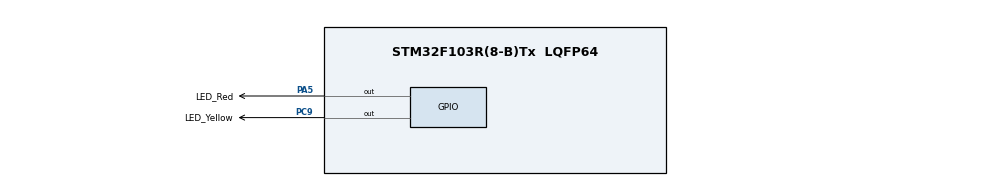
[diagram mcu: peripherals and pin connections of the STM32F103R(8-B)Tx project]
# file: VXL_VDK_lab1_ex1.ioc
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Mcu.Family=STM32F1
Mcu.Name=STM32F103R(8-B)Tx
Mcu.Package=LQFP64
NVIC.PriorityGroup=NVIC_PRIORITYGROUP_4
PA13.Mode=Serial_Wire
PA13.Signal=SYS_JTMS-SWDIO
PA14.Mode=Serial_Wire
PA14.Signal=SYS_JTCK-SWCLK
PA5.GPIO_Label=LED_Red
PA5.Signal=GPIO_Output
PC9.GPIO_Label=LED_Yellow
PC9.Signal=GPIO_Output
ProjectManager.HeapSize=0x200
ProjectManager.StackSize=0x400
ProjectManager.TargetToolchain=STM32CubeIDE
RCC.APB1Freq_Value=8000000
RCC.APB2Freq_Value=8000000
board=custom

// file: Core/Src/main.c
/* USER CODE BEGIN Header */
/**
  ******************************************************************************
  * @file           : main.c
  * @brief          : Main program body
  ******************************************************************************
  * @attention
  *
  * Copyright (c) 2025 STMicroelectronics.
  * All rights reserved.
  *
  * This software is licensed under terms that can be found in the LICENSE file
  * in the root directory of this software component.
  * If no LICENSE file comes with this software, it is provided AS-IS.
  *
  ******************************************************************************
  */
/* USER CODE END Header */
#include "main.h"

/* USER CODE BEGIN PM */
#define TIMER_SCALE 100
/* USER CODE END PM */

/* USER CODE BEGIN PV */
uint16_t timer_cnt = TIMER_SCALE;
uint8_t timer_flag = RESET;
/* USER CODE END PV */

void SystemClock_Config(void);
static void MX_GPIO_Init(void);
/* USER CODE BEGIN PFP */
void timer_handle();
/* USER CODE END PFP */

/* USER CODE BEGIN 0 */
void timer_handle(){
	if(timer_cnt <= 0){
		timer_flag = SET;
		timer_cnt = TIMER_SCALE;
	}
	else --timer_cnt;
}
/* USER CODE END 0 */

int main(void)
{

  /* USER CODE BEGIN 1 */
	  uint8_t led_time = 0;
	  uint8_t led_status = 0;
  /* USER CODE END 1 */

  /* MCU Configuration--------------------------------------------------------*/

  /* Reset of all peripherals, Initializes the Flash interface and the Systick. */
  HAL_Init();

  /* Configure the system clock */
  SystemClock_Config();

  /* Initialize all configured peripherals */
  MX_GPIO_Init();

  /* Infinite loop */
  /* USER CODE BEGIN WHILE */
  while (1)
  {
	  timer_handle();
	  if(timer_flag){
		  timer_flag = RESET;
		  ++led_time;
	  }
	  /*LED BEHAVIOR CODE BEGIN*/
	  if(led_time >=2){
		  led_status = 1 - led_status;
		  led_time = 0;
	  }
	  if(led_status == 0){
		  HAL_GPIO_WritePin(LED_Red_GPIO_Port, LED_Red_Pin, SET);
		  HAL_GPIO_WritePin(LED_Yellow_GPIO_Port, LED_Yellow_Pin, RESET);
	  }else{
		  HAL_GPIO_WritePin(LED_Red_GPIO_Port, LED_Red_Pin, RESET);
		  HAL_GPIO_WritePin(LED_Yellow_GPIO_Port, LED_Yellow_Pin, SET);
	  	  }
	  /*LED BEHAVIOR CODE END*/

	  HAL_Delay(10);
    /* USER CODE END WHILE */

  }
}

void SystemClock_Config(void)
{
  RCC_OscInitTypeDef RCC_OscInitStruct = {0};
  RCC_ClkInitTypeDef RCC_ClkInitStruct = {0};

  /** Initializes the RCC Oscillators according to the specified parameters
  * in the RCC_OscInitTypeDef structure.
  */
  RCC_OscInitStruct.OscillatorType = RCC_OSCILLATORTYPE_HSI;
  RCC_OscInitStruct.HSIState = RCC_HSI_ON;
  RCC_OscInitStruct.HSICalibrationValue = RCC_HSICALIBRATION_DEFAULT;
  RCC_OscInitStruct.PLL.PLLState = RCC_PLL_NONE;
  if (HAL_RCC_OscConfig(&RCC_OscInitStruct) != HAL_OK)
  {
    Error_Handler();
  }

  /** Initializes the CPU, AHB and APB buses clocks
  */
  RCC_ClkInitStruct.ClockType = RCC_CLOCKTYPE_HCLK|RCC_CLOCKTYPE_SYSCLK
                              |RCC_CLOCKTYPE_PCLK1|RCC_CLOCKTYPE_PCLK2;
  RCC_ClkInitStruct.SYSCLKSource = RCC_SYSCLKSOURCE_HSI;
  RCC_ClkInitStruct.AHBCLKDivider = RCC_SYSCLK_DIV1;
  RCC_ClkInitStruct.APB1CLKDivider = RCC_HCLK_DIV1;
  RCC_ClkInitStruct.APB2CLKDivider = RCC_HCLK_DIV1;

  if (HAL_RCC_ClockConfig(&RCC_ClkInitStruct, FLASH_LATENCY_0) != HAL_OK)
  {
    Error_Handler();
  }
}

static void MX_GPIO_Init(void)
{
  GPIO_InitTypeDef GPIO_InitStruct = {0};

  /* GPIO Ports Clock Enable */
  __HAL_RCC_GPIOA_CLK_ENABLE();
  __HAL_RCC_GPIOC_CLK_ENABLE();

  /*Configure GPIO pin Output Level */
  HAL_GPIO_WritePin(LED_Red_GPIO_Port, LED_Red_Pin, GPIO_PIN_RESET);

  /*Configure GPIO pin Output Level */
  HAL_GPIO_WritePin(LED_Yellow_GPIO_Port, LED_Yellow_Pin, GPIO_PIN_RESET);

  /*Configure GPIO pin : LED_Red_Pin */
  GPIO_InitStruct.Pin = LED_Red_Pin;
  GPIO_InitStruct.Mode = GPIO_MODE_OUTPUT_PP;
  GPIO_InitStruct.Pull = GPIO_NOPULL;
  GPIO_InitStruct.Speed = GPIO_SPEED_FREQ_LOW;
  HAL_GPIO_Init(LED_Red_GPIO_Port, &GPIO_InitStruct);

  /*Configure GPIO pin : LED_Yellow_Pin */
  GPIO_InitStruct.Pin = LED_Yellow_Pin;
  GPIO_InitStruct.Mode = GPIO_MODE_OUTPUT_PP;
  GPIO_InitStruct.Pull = GPIO_NOPULL;
  GPIO_InitStruct.Speed = GPIO_SPEED_FREQ_LOW;
  HAL_GPIO_Init(LED_Yellow_GPIO_Port, &GPIO_InitStruct);

}

void Error_Handler(void)
{
  __disable_irq();
  while (1)
  {
  }
}
